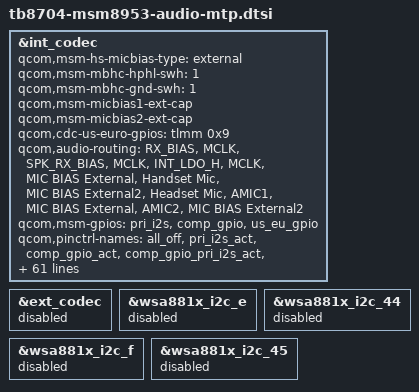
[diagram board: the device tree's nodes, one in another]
&int_codec {
	qcom,msm-hs-micbias-type = "external";
	qcom,msm-mbhc-hphl-swh = <1>;
	qcom,msm-mbhc-gnd-swh = <1>;
	qcom,msm-micbias1-ext-cap;
	qcom,msm-micbias2-ext-cap;
	qcom,cdc-us-euro-gpios;
	qcom,cdc-us-euro-gpios = <&tlmm 0x9 0x0>;
	qcom,audio-routing = "RX_BIAS",
			    "MCLK",
			    "SPK_RX_BIAS",
			    "MCLK",
			    "INT_LDO_H",
			    "MCLK",
			    "MIC BIAS External",
			    "Handset Mic",
			    "MIC BIAS External2",
			    "Headset Mic",
			    "AMIC1",
			    "MIC BIAS External",
			    "AMIC2",
			    "MIC BIAS External2";
	pinctrl-names = "all_off",
			"pri_i2s_act",
			"comp_gpio_act",
			"comp_gpio_pri_i2s_act",
			"us_eu_gpio_act",
			"pri_i2s_us_eu_gpio_act";
	qcom,msm-gpios = "pri_i2s",
			"comp_gpio",
			"us_eu_gpio";

	qcom,pinctrl-names = "all_off",
			"pri_i2s_act",
			"comp_gpio_act",
			"comp_gpio_pri_i2s_act",
			"us_eu_gpio_act",
			"pri_i2s_us_eu_gpio_act";
	pinctrl-0 = <&cdc_pdm_lines_sus &cdc_pdm_comp_lines_sus &cdc_pdm_lines_2_sus &cross_conn_det_sus>;
	pinctrl-1 = <&cdc_pdm_lines_act &cdc_pdm_comp_lines_sus &cdc_pdm_lines_2_act &cross_conn_det_sus>;
	pinctrl-2 = <&cdc_pdm_lines_sus &cdc_pdm_comp_lines_act &cdc_pdm_lines_2_sus &cross_conn_det_sus>;
	pinctrl-3 = <&cdc_pdm_lines_act &cdc_pdm_comp_lines_act &cdc_pdm_lines_2_act &cross_conn_det_sus>;
	pinctrl-4 = <&cdc_pdm_lines_sus &cdc_pdm_comp_lines_sus &cdc_pdm_lines_2_sus &cross_conn_det_act>;
	pinctrl-5 = <&cdc_pdm_lines_act &cdc_pdm_comp_lines_sus &cdc_pdm_lines_2_act &cross_conn_det_act>;
	pinctrl-6 = <&cdc_pdm_lines_sus &cdc_pdm_comp_lines_sus &cdc_pdm_lines_2_sus &cross_conn_det_act &pri_tlmm_lines_act &pri_tlmm_ws_act>;
	pinctrl-7 = <&cdc_pdm_lines_act &cdc_pdm_comp_lines_sus &cdc_pdm_lines_2_act &cross_conn_det_act &pri_tlmm_lines_act &pri_tlmm_ws_act>;
	pinctrl-8 = <&cdc_pdm_lines_sus &cdc_pdm_comp_lines_act &cdc_pdm_lines_2_sus &cross_conn_det_sus &pri_tlmm_lines_sus &pri_tlmm_ws_sus>;
	pinctrl-9 = <&cdc_pdm_lines_act &cdc_pdm_comp_lines_act &cdc_pdm_lines_2_act &cross_conn_det_sus &pri_tlmm_lines_sus &pri_tlmm_ws_sus>;
	pinctrl-10 = <&cdc_pdm_lines_sus &cdc_pdm_comp_lines_act &cdc_pdm_lines_2_sus &cross_conn_det_act &pri_tlmm_lines_sus &pri_tlmm_ws_sus>;
	pinctrl-11 = <&cdc_pdm_lines_act &cdc_pdm_comp_lines_act &cdc_pdm_lines_2_act &cross_conn_det_act &pri_tlmm_lines_sus &pri_tlmm_ws_sus>;
	pinctrl-12 = <&cdc_pdm_lines_sus &cdc_pdm_comp_lines_act &cdc_pdm_lines_2_sus &cross_conn_det_sus &pri_tlmm_lines_act &pri_tlmm_ws_act>;
	pinctrl-13 = <&cdc_pdm_lines_act &cdc_pdm_comp_lines_act &cdc_pdm_lines_2_act &cross_conn_det_sus &pri_tlmm_lines_act &pri_tlmm_ws_act>;
	pinctrl-14 = <&cdc_pdm_lines_sus &cdc_pdm_comp_lines_act &cdc_pdm_lines_2_sus &cross_conn_det_act &pri_tlmm_lines_act &pri_tlmm_ws_act>;
	pinctrl-15 = <&cdc_pdm_lines_act &cdc_pdm_comp_lines_act &cdc_pdm_lines_2_act &cross_conn_det_act &pri_tlmm_lines_act &pri_tlmm_ws_act>;

	qcom,spk_ext_pa_l = <&tlmm 0x86 0x0>;
	qcom,spk_ext_pa_r = <&tlmm 0x6 0x0>;

};

&ext_codec {
	status = "disabled";
};

&wsa881x_i2c_e {
	status = "disabled";
};

&wsa881x_i2c_44 {
	status = "disabled";
};

&wsa881x_i2c_f {
	status = "disabled";
};

&wsa881x_i2c_45 {
	status = "disabled";
};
